# M470 register map
File version: 2.0.2.5
Registers are 32-bit, read-write, reset 0x0 unless marked. A register's access mark holds for its fields unless they carry their own. Offsets are from the block's base; [hi:lo] are bit positions; {n}, {i} and the like mark numbered series.

## PB — Port B
Base 0x400C0100
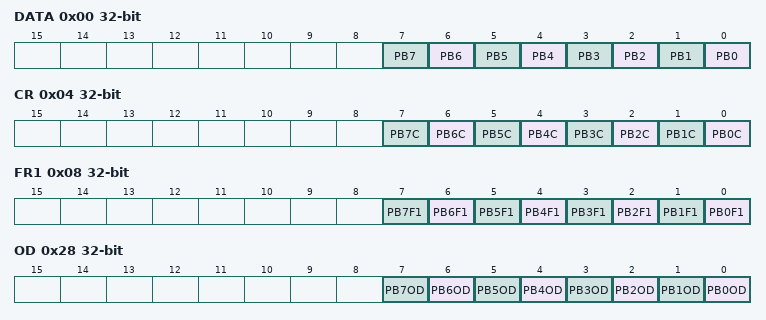
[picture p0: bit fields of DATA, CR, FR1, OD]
0x00 DATA — Port B Data Register
  [n] PB{n} (n=0..7)
0x04 CR — Port B Output Control Register
  [n] PB{n}C (n=0..7)
0x08 FR1 — Port B Function Register 1
  [n] PB{n}F1 (n=0..7)
0x28 OD — Port B Open Drain Control Register
  [n] PB{n}OD (n=0..7)
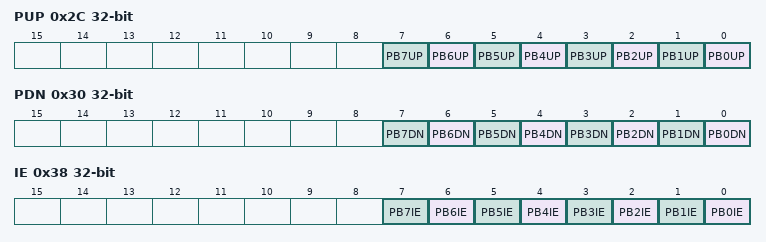
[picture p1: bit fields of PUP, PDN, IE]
0x2C PUP — Port B Pull-up Control Register
  [n] PB{n}UP (n=0..7)
0x30 PDN — Port B Pull-down Control Register
  [n] PB{n}DN (n=0..7)
0x38 IE — Port B Input Control Register
  [n] PB{n}IE (n=0..7)

## PC — Port C
Base 0x400C0200
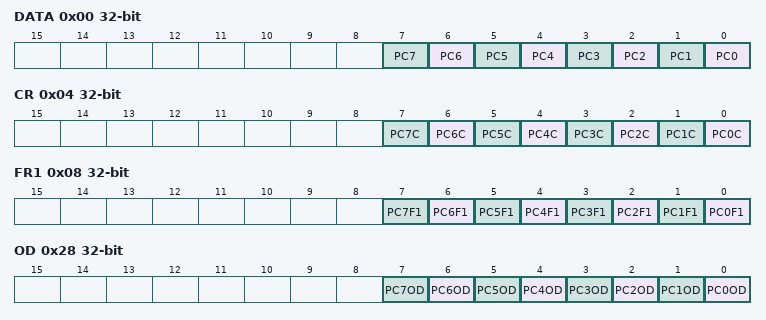
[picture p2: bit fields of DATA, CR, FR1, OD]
0x00 DATA — Port C Data Register
  [n] PC{n} (n=0..7)
0x04 CR — Port C Output Control Register
  [n] PC{n}C (n=0..7)
0x08 FR1 — Port C Function Register 1
  [n] PC{n}F1 (n=0..7)
0x28 OD — Port C Open Drain Control Register
  [n] PC{n}OD (n=0..7)
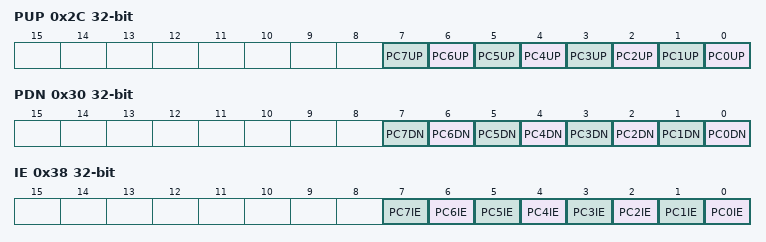
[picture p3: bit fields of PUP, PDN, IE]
0x2C PUP — Port C Pull-up Control Register
  [n] PC{n}UP (n=0..7)
0x30 PDN — Port C Pull-down Control Register
  [n] PC{n}DN (n=0..7)
0x38 IE — Port C Input Control Register
  [n] PC{n}IE (n=0..7)

## PD — Port D
Base 0x400C0300
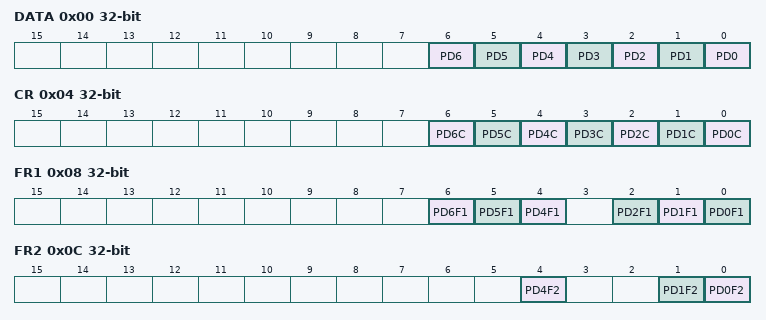
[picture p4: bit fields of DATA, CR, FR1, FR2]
0x00 DATA — Port D Data Register
  [n] PD{n} (n=0..6)
0x04 CR — Port D Output Control Register
  [n] PD{n}C (n=0..6)
0x08 FR1 — Port D Function Register 1
  [6] PD6F1, [5] PD5F1, [4] PD4F1, [2] PD2F1, [1] PD1F1, [0] PD0F1
0x0C FR2 — Port D Function Register 2
  [4] PD4F2, [1] PD1F2, [0] PD0F2
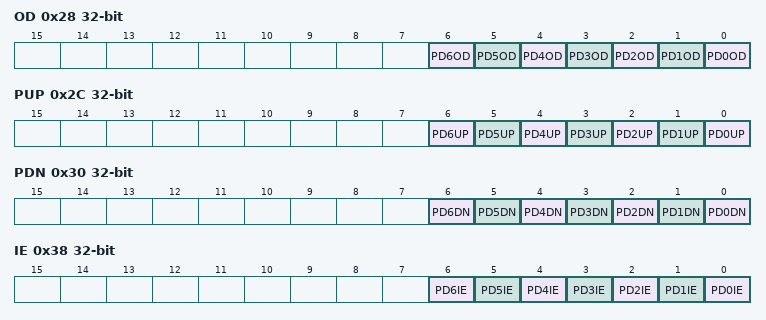
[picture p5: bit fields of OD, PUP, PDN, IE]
0x28 OD — Port D Open Drain Control Register
  [n] PD{n}OD (n=0..6)
0x2C PUP — Port D Pull-up Control Register
  [n] PD{n}UP (n=0..6)
0x30 PDN — Port D Pull-down Control Register
  [n] PD{n}DN (n=0..6)
0x38 IE — Port D Input Control Register
  [n] PD{n}IE (n=0..6)

## PE — Port E
Base 0x400C0400
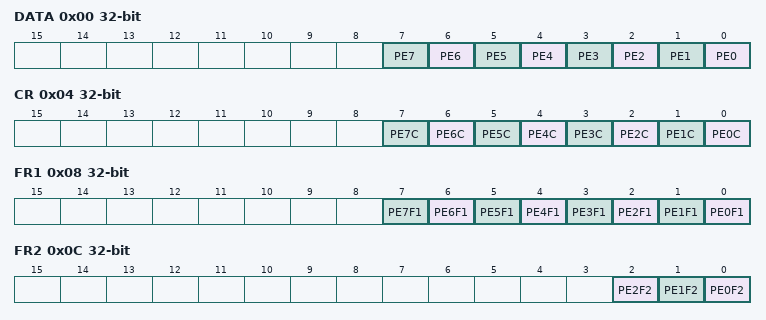
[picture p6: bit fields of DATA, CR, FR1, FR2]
0x00 DATA — Port E Data Register
  [n] PE{n} (n=0..7)
0x04 CR — Port E Output Control Register
  [n] PE{n}C (n=0..7)
0x08 FR1 — Port E Function Register 1
  [n] PE{n}F1 (n=0..7)
0x0C FR2 — Port E Function Register 2
  [2] PE2F2, [1] PE1F2, [0] PE0F2
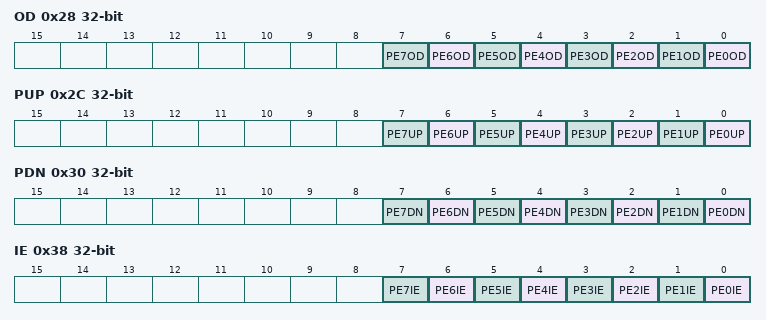
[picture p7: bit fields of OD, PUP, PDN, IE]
0x28 OD — Port E Open Drain Control Register
  [n] PE{n}OD (n=0..7)
0x2C PUP — Port E Pull-up Control Register
  [n] PE{n}UP (n=0..7)
0x30 PDN — Port E Pull-down Control Register
  [n] PE{n}DN (n=0..7)
0x38 IE — Port E Input Control Register
  [n] PE{n}IE (n=0..7)

## PF — Port F
Base 0x400C0500
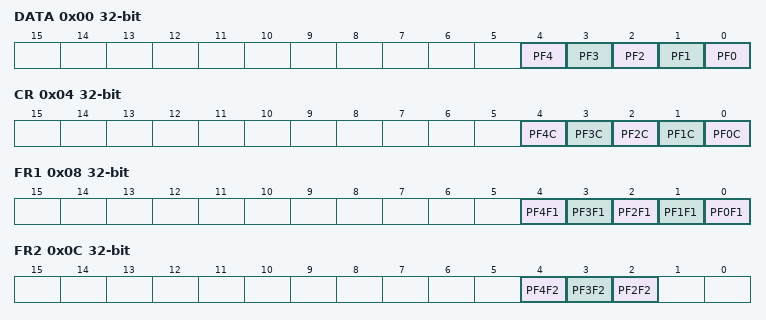
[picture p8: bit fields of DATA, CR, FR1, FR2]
0x00 DATA — Port F Data Register
  [n] PF{n} (n=0..4)
0x04 CR — Port F Output Control Register
  [n] PF{n}C (n=0..4)
0x08 FR1 — Port F Function Register 1
  [n] PF{n}F1 (n=0..4)
0x0C FR2 — Port F Function Register 2
  [4] PF4F2, [3] PF3F2, [2] PF2F2
0x10 FR3 — Port F Function Register 3
  [2] PF2F3
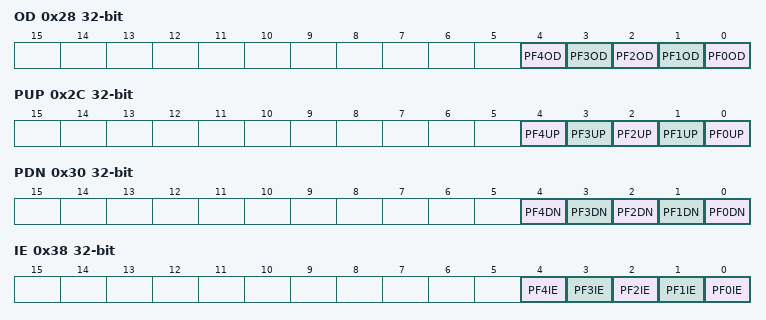
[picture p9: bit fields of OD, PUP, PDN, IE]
0x28 OD — Port F Open Drain Control Register
  [n] PF{n}OD (n=0..4)
0x2C PUP — Port F Pull-up Control Register
  [n] PF{n}UP (n=0..4)
0x30 PDN — Port F Pull-down Control Register
  [n] PF{n}DN (n=0..4)
0x38 IE — Port F Input Control Register
  [n] PF{n}IE (n=0..4)

## PG — Port G
Base 0x400C0600
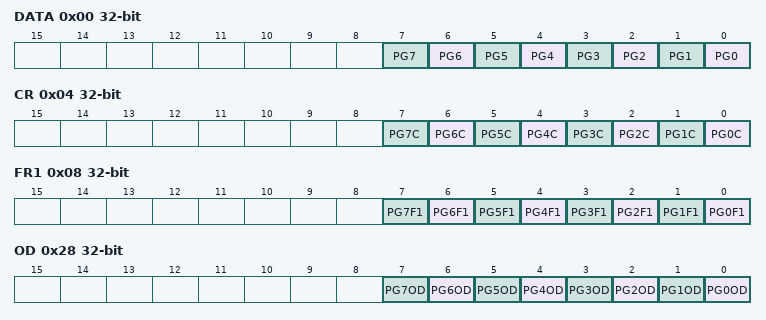
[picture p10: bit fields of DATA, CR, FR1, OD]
0x00 DATA — Port G Data Register
  [n] PG{n} (n=0..7)
0x04 CR — Port G Output Control Register
  [n] PG{n}C (n=0..7)
0x08 FR1 — Port G Function Register 1
  [n] PG{n}F1 (n=0..7)
0x28 OD — Port G Open Drain Control Register
  [n] PG{n}OD (n=0..7)
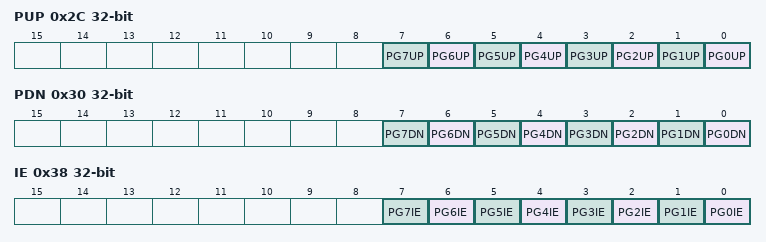
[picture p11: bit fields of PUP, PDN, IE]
0x2C PUP — Port G Pull-up Control Register
  [n] PG{n}UP (n=0..7)
0x30 PDN — Port G Pull-down Control Register
  [n] PG{n}DN (n=0..7)
0x38 IE — Port G Input Control Register
  [n] PG{n}IE (n=0..7)

## PH — Port H
Base 0x400C0700
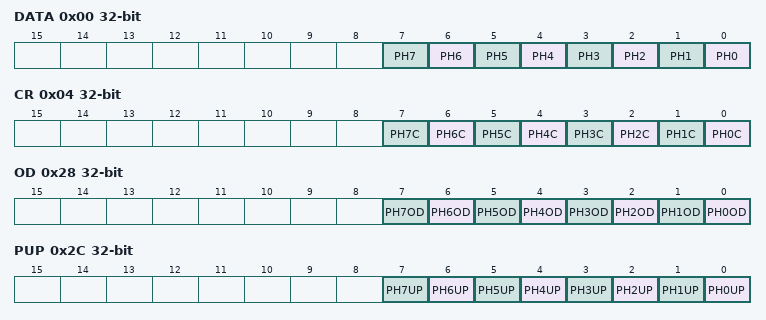
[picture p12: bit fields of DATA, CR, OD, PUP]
0x00 DATA — Port H Data Register
  [n] PH{n} (n=0..7)
0x04 CR — Port H Output Control Register
  [n] PH{n}C (n=0..7)
0x28 OD — Port H Open Drain Control Register
  [n] PH{n}OD (n=0..7)
0x2C PUP — Port H Pull-up Control Register
  [n] PH{n}UP (n=0..7)
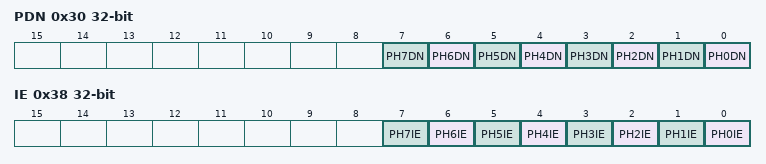
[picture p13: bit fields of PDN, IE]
0x30 PDN — Port H Pull-down Control Register
  [n] PH{n}DN (n=0..7)
0x38 IE — Port H Input Control Register
  [n] PH{n}IE (n=0..7)

## PJ — Port J
Base 0x400C0800
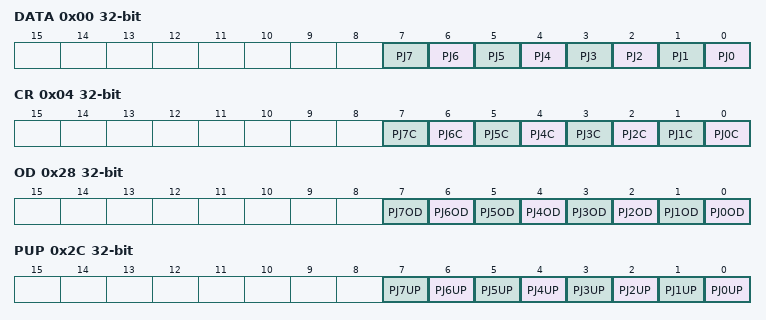
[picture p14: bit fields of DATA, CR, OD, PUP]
0x00 DATA — Port J Data Register
  [n] PJ{n} (n=0..7)
0x04 CR — Port J Output Control Register
  [n] PJ{n}C (n=0..7)
0x28 OD — Port J Open Drain Control Register
  [n] PJ{n}OD (n=0..7)
0x2C PUP — Port J Pull-up Control Register
  [n] PJ{n}UP (n=0..7)
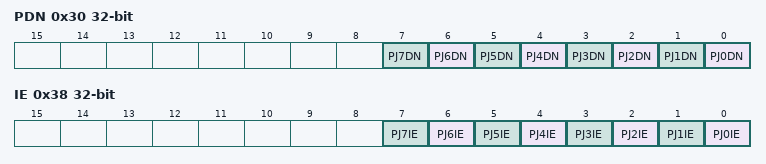
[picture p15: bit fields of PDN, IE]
0x30 PDN — Port J Pull-down Control Register
  [n] PJ{n}DN (n=0..7)
0x38 IE — Port J Input Control Register
  [n] PJ{n}IE (n=0..7)
